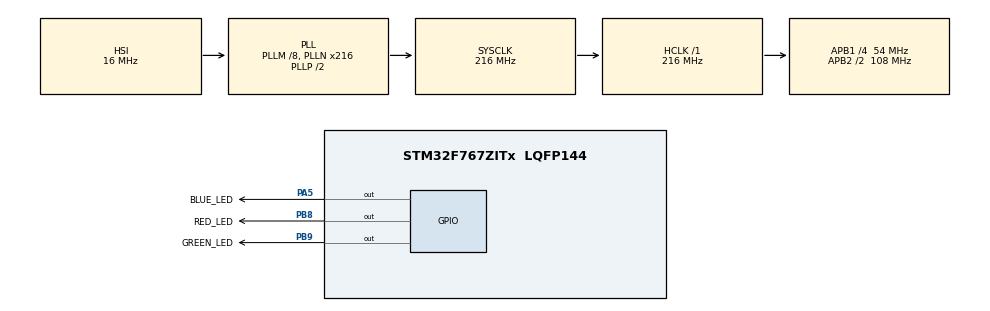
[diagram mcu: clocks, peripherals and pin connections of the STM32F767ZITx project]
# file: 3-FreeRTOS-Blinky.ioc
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CORTEX_M7.default_mode_Activation=1
FREERTOS.Tasks01=defaultTask,24,128,StartDefaultTask,Default,NULL,Dynamic,NULL,NULL
FREERTOS.configUSE_NEWLIB_REENTRANT=1
Mcu.Family=STM32F7
Mcu.Name=STM32F767ZITx
Mcu.Package=LQFP144
NVIC.PriorityGroup=NVIC_PRIORITYGROUP_4
NVIC.TIM1_UP_TIM10_IRQn=true\:15\:0\:false\:false\:true\:false\:false\:true\:true
NVIC.TimeBase=TIM1_UP_TIM10_IRQn
NVIC.TimeBaseIP=TIM1
PA5.GPIO_Label=BLUE_LED
PA5.Signal=GPIO_Output
PB8.GPIO_Label=RED_LED
PB8.Signal=GPIO_Output
PB9.GPIO_Label=GREEN_LED
PB9.Signal=GPIO_Output
PH0/OSC_IN.Mode=HSE-External-Oscillator
PH0/OSC_IN.Signal=RCC_OSC_IN
PH1/OSC_OUT.Mode=HSE-External-Oscillator
PH1/OSC_OUT.Signal=RCC_OSC_OUT
ProjectManager.HeapSize=0x200
ProjectManager.StackSize=0x400
ProjectManager.TargetToolchain=STM32CubeIDE
RCC.AHBFreq_Value=216000000
RCC.APB1CLKDivider=RCC_HCLK_DIV4
RCC.APB1Freq_Value=54000000
RCC.APB1TimFreq_Value=108000000
RCC.APB2CLKDivider=RCC_HCLK_DIV2
RCC.APB2Freq_Value=108000000
RCC.APB2TimFreq_Value=216000000
RCC.CortexFreq_Value=216000000
RCC.HCLKFreq_Value=216000000
RCC.HSE_VALUE=25000000
RCC.HSI_VALUE=16000000
RCC.LSE_VALUE=32768
RCC.PLLM=8
RCC.PLLN=216
RCC.SYSCLKFreq_VALUE=216000000
RCC.SYSCLKSource=RCC_SYSCLKSOURCE_PLLCLK
RCC.USBFreq_Value=216000000
RCC.VCOOutputFreq_Value=432000000
VP_FREERTOS_VS_CMSIS_V2.Mode=CMSIS_V2
VP_SYS_VS_tim1.Mode=TIM1
board=custom

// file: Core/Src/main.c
/* USER CODE BEGIN Header */
/**
  ******************************************************************************
  * @file           : main.c
  * @brief          : Main program body
  ******************************************************************************
  * @attention
  *
  * Copyright (c) 2025 STMicroelectronics.
  * All rights reserved.
  *
  * This software is licensed under terms that can be found in the LICENSE file
  * in the root directory of this software component.
  * If no LICENSE file comes with this software, it is provided AS-IS.
  *
  ******************************************************************************
  */
/* USER CODE END Header */
#include "main.h"
#include "cmsis_os.h"

/* USER CODE BEGIN PD */
#define STACK_SIZE 128 * 4
#define RED_TIMER_LENGTH 2400
#define RED_PERIOD 1000
#define BLUE_PERIOD 400
#define GREEN_PERIOD 1200
/* USER CODE END PD */

/* Definitions for defaultTask */

/* USER CODE BEGIN PV */
osThreadId_t redTaskHandle;
const osThreadAttr_t redTask_attributes = {
  .name = "redTask",
  .stack_size = STACK_SIZE,
  .priority = (osPriority_t) osPriorityNormal,
};

osThreadId_t greenTaskHandle;
const osThreadAttr_t greenTask_attributes = {
  .name = "greenTask",
  .stack_size = STACK_SIZE,
  .priority = (osPriority_t) osPriorityNormal,
};

osThreadId_t blueTaskHandle;
const osThreadAttr_t blueTask_attributes = {
  .name = "blueTask",
  .stack_size = STACK_SIZE,
  .priority = (osPriority_t) osPriorityNormal,
};

osTimerId_t red_timer;
const osTimerAttr_t red_timer_atrr = {
		.name = "redTimer",
		.attr_bits = 0,
		.cb_mem = NULL,
		.cb_size = 0
};
/* USER CODE END PV */

void SystemClock_Config(void);
static void MPU_Config(void);
static void MX_GPIO_Init(void);

/* USER CODE BEGIN PFP */
void BlueBlinkTask(void* arg);
void GreenBlinkTask(void* arg);
void RedBlinkTask(void* arg);
void red_timer_Callback(void* arg);
/* USER CODE END PFP */

int main(void)
{

  /* MPU Configuration--------------------------------------------------------*/
  MPU_Config();

  /* MCU Configuration--------------------------------------------------------*/

  /* Reset of all peripherals, Initializes the Flash interface and the Systick. */
  HAL_Init();

  /* Configure the system clock */
  SystemClock_Config();

  /* Initialize all configured peripherals */
  MX_GPIO_Init();

  /* Init scheduler */
  osKernelInitialize();

  /* USER CODE BEGIN RTOS_TIMERS */
  red_timer = osTimerNew(red_timer_Callback, osTimerOnce, NULL, &red_timer_atrr);
  osTimerStart(red_timer, RED_TIMER_LENGTH);
  /* USER CODE END RTOS_TIMERS */

  /* Create the thread(s) */
  /* creation of defaultTask */

  /* USER CODE BEGIN RTOS_THREADS */
  greenTaskHandle = osThreadNew(GreenBlinkTask, NULL, &greenTask_attributes);
  blueTaskHandle = osThreadNew(BlueBlinkTask, NULL, &blueTask_attributes);
  /* USER CODE END RTOS_THREADS */

  /* Start scheduler */
  osKernelStart();

  /* We should never get here as control is now taken by the scheduler */

  /* Infinite loop */
  while (1)
  {

  }
}

void SystemClock_Config(void)
{
  RCC_OscInitTypeDef RCC_OscInitStruct = {0};
  RCC_ClkInitTypeDef RCC_ClkInitStruct = {0};

  /** Configure the main internal regulator output voltage
  */
  __HAL_RCC_PWR_CLK_ENABLE();
  __HAL_PWR_VOLTAGESCALING_CONFIG(PWR_REGULATOR_VOLTAGE_SCALE1);

  /** Initializes the RCC Oscillators according to the specified parameters
  * in the RCC_OscInitTypeDef structure.
  */
  RCC_OscInitStruct.OscillatorType = RCC_OSCILLATORTYPE_HSI;
  RCC_OscInitStruct.HSIState = RCC_HSI_ON;
  RCC_OscInitStruct.HSICalibrationValue = RCC_HSICALIBRATION_DEFAULT;
  RCC_OscInitStruct.PLL.PLLState = RCC_PLL_ON;
  RCC_OscInitStruct.PLL.PLLSource = RCC_PLLSOURCE_HSI;
  RCC_OscInitStruct.PLL.PLLM = 8;
  RCC_OscInitStruct.PLL.PLLN = 216;
  RCC_OscInitStruct.PLL.PLLP = RCC_PLLP_DIV2;
  RCC_OscInitStruct.PLL.PLLQ = 2;
  RCC_OscInitStruct.PLL.PLLR = 2;
  if (HAL_RCC_OscConfig(&RCC_OscInitStruct) != HAL_OK)
  {
    Error_Handler();
  }

  /** Activate the Over-Drive mode
  */
  if (HAL_PWREx_EnableOverDrive() != HAL_OK)
  {
    Error_Handler();
  }

  /** Initializes the CPU, AHB and APB buses clocks
  */
  RCC_ClkInitStruct.ClockType = RCC_CLOCKTYPE_HCLK|RCC_CLOCKTYPE_SYSCLK
                              |RCC_CLOCKTYPE_PCLK1|RCC_CLOCKTYPE_PCLK2;
  RCC_ClkInitStruct.SYSCLKSource = RCC_SYSCLKSOURCE_PLLCLK;
  RCC_ClkInitStruct.AHBCLKDivider = RCC_SYSCLK_DIV1;
  RCC_ClkInitStruct.APB1CLKDivider = RCC_HCLK_DIV4;
  RCC_ClkInitStruct.APB2CLKDivider = RCC_HCLK_DIV2;

  if (HAL_RCC_ClockConfig(&RCC_ClkInitStruct, FLASH_LATENCY_7) != HAL_OK)
  {
    Error_Handler();
  }
}

static void MX_GPIO_Init(void)
{
  GPIO_InitTypeDef GPIO_InitStruct = {0};

  /* GPIO Ports Clock Enable */
  __HAL_RCC_GPIOH_CLK_ENABLE();
  __HAL_RCC_GPIOA_CLK_ENABLE();
  __HAL_RCC_GPIOB_CLK_ENABLE();

  /*Configure GPIO pin Output Level */
  HAL_GPIO_WritePin(BLUE_LED_GPIO_Port, BLUE_LED_Pin, GPIO_PIN_RESET);

  /*Configure GPIO pin Output Level */
  HAL_GPIO_WritePin(GPIOB, RED_LED_Pin|GREEN_LED_Pin, GPIO_PIN_RESET);

  /*Configure GPIO pin : BLUE_LED_Pin */
  GPIO_InitStruct.Pin = BLUE_LED_Pin;
  GPIO_InitStruct.Mode = GPIO_MODE_OUTPUT_PP;
  GPIO_InitStruct.Pull = GPIO_NOPULL;
  GPIO_InitStruct.Speed = GPIO_SPEED_FREQ_LOW;
  HAL_GPIO_Init(BLUE_LED_GPIO_Port, &GPIO_InitStruct);

  /*Configure GPIO pins : RED_LED_Pin GREEN_LED_Pin */
  GPIO_InitStruct.Pin = RED_LED_Pin|GREEN_LED_Pin;
  GPIO_InitStruct.Mode = GPIO_MODE_OUTPUT_PP;
  GPIO_InitStruct.Pull = GPIO_NOPULL;
  GPIO_InitStruct.Speed = GPIO_SPEED_FREQ_LOW;
  HAL_GPIO_Init(GPIOB, &GPIO_InitStruct);

}

/* USER CODE BEGIN 4 */
void BlueBlinkTask(void* arg) {
	while (1) {
		HAL_GPIO_TogglePin(GPIOA, BLUE_LED_Pin);
		osDelay(BLUE_PERIOD / 2);
	}
}

void GreenBlinkTask(void* arg) {
	while (1) {
		HAL_GPIO_TogglePin(GPIOB, GREEN_LED_Pin);
		osDelay(GREEN_PERIOD / 2);
	}
}

void RedBlinkTask(void* arg) {
	while(1) {
		HAL_GPIO_TogglePin(GPIOB, RED_LED_Pin);
		osDelay(RED_PERIOD / 2);
	}
}

void red_timer_Callback(void* arg) {
	osThreadTerminate(blueTaskHandle);
	osThreadTerminate(greenTaskHandle);

	redTaskHandle = osThreadNew(RedBlinkTask, NULL, &redTask_attributes);
}
/* USER CODE END 4 */

 /* MPU Configuration */

void MPU_Config(void)
{
  MPU_Region_InitTypeDef MPU_InitStruct = {0};

  /* Disables the MPU */
  HAL_MPU_Disable();

  /** Initializes and configures the Region and the memory to be protected
  */
  MPU_InitStruct.Enable = MPU_REGION_ENABLE;
  MPU_InitStruct.Number = MPU_REGION_NUMBER0;
  MPU_InitStruct.BaseAddress = 0x0;
  MPU_InitStruct.Size = MPU_REGION_SIZE_4GB;
  MPU_InitStruct.SubRegionDisable = 0x87;
  MPU_InitStruct.TypeExtField = MPU_TEX_LEVEL0;
  MPU_InitStruct.AccessPermission = MPU_REGION_NO_ACCESS;
  MPU_InitStruct.DisableExec = MPU_INSTRUCTION_ACCESS_DISABLE;
  MPU_InitStruct.IsShareable = MPU_ACCESS_SHAREABLE;
  MPU_InitStruct.IsCacheable = MPU_ACCESS_NOT_CACHEABLE;
  MPU_InitStruct.IsBufferable = MPU_ACCESS_NOT_BUFFERABLE;

  HAL_MPU_ConfigRegion(&MPU_InitStruct);
  /* Enables the MPU */
  HAL_MPU_Enable(MPU_PRIVILEGED_DEFAULT);

}

void HAL_TIM_PeriodElapsedCallback(TIM_HandleTypeDef *htim)
{
  if (htim->Instance == TIM1) {
    HAL_IncTick();
  }
}

void Error_Handler(void)
{
  __disable_irq();
  while (1)
  {
  }
}
